# APM32F103xD register map
File version: 1.0
CPU: CM3 r2p1, little endian, no MPU, no FPU, 4 interrupt priority bits
Registers are 32-bit, read-write, reset 0x0 unless marked. A register's access mark holds for its fields unless they carry their own. Offsets are from the block's base; [hi:lo] are bit positions.

## IWDT — Independent watchdog
Base 0x40003000
0x00 KEY wo — Key register (IWDT_KEY)
  [15:0] KEY — Key value
0x04 PSC — Frequency Divider register (IWDT_PSC)
  [2:0] PSC — Prescaler divider
0x08 CNTRLD reset 0xFFF — Reload values register (IWDT_CNTRLD)
  [11:0] CNTRLD — Watchdog counter reload value
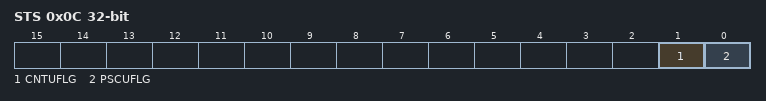
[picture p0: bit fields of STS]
0x0C STS ro — Status register (IWDT_STS)
  [1] CNTUFLG — Watchdog counter reload value update
  [0] PSCUFLG — Watchdog prescaler value update

## WWDT — Window watchdog
Base 0x40002C00
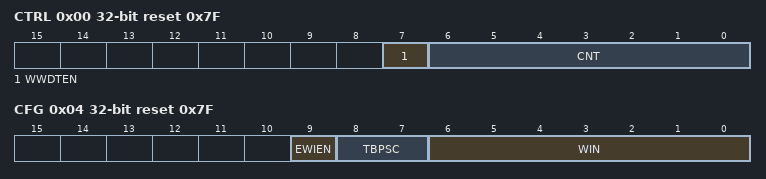
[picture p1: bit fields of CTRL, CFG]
0x00 CTRL reset 0x7F — Control register (WWDT_CTRL)
  [7] WWDTEN — Activation bit
  [6:0] CNT — 7-bit counter (MSB to LSB)
0x04 CFG reset 0x7F — Configuration register (WWDT_CFG)
  [9] EWIEN — Early Wakeup Interrupt
  [8:7] TBPSC — Timer Base
  [6:0] WIN — 7-bit window value
0x08 STS — Status register (WWDT_STS)
  [0] EWIFLG — Early Wakeup Interrupt

## RTC — Real time clock
Base 0x40002800
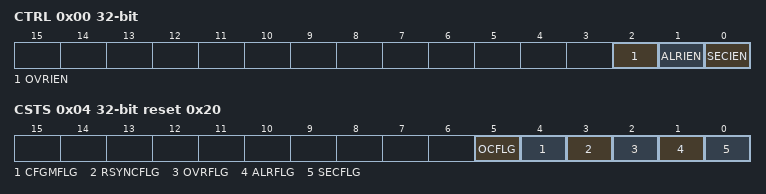
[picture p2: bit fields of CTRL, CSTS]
0x00 CTRL — Control register
  [2] OVRIEN — Overflow interrupt Enable
  [1] ALRIEN — Alarm interrupt Enable
  [0] SECIEN — Second interrupt Enable
0x04 CSTS access per field reset 0x20 — Control and State register
  [5] OCFLG ro — RTC operation OFF
  [4] CFGMFLG rw — Configuration Flag
  [3] RSYNCFLG rw — Registers Synchronized Flag
  [2] OVRFLG rw — Overflow Flag
  [1] ALRFLG rw — Alarm Flag
  [0] SECFLG rw — Second Flag
0x08 PSCRLDH wo — RTC predivision loading register High Bit
  [3:0] PSCRLDH — RTC Prescaler Load Register High
0x0C PSCRLDL wo reset 0x8000 — RTC predivision loading register Low Bit
  [15:0] PSCRLDL — RTC Prescaler Divider Register Low
0x10 PSCH ro — RTC predivider remainder register High Bit
  [3:0] PSCH — RTC prescaler divider register high
0x14 PSCL ro reset 0x8000 — RTC predivider remainder register Low Bit
  [15:0] PSCL — RTC prescaler divider register Low
0x18 CNTH — RTC count register High Bit
  [15:0] CNTH — RTC counter register high
0x1C CNTL — RTC count register Low Bit
  [15:0] CNTL — RTC counter register Low
0x20 ALRH wo reset 0xFFFF — RTC alarm clock register High Bit
  [15:0] ALRH — RTC alarm register high
0x24 ALRL wo reset 0xFFFF — RTC alarm clock register Low Bit
  [15:0] ALRL — RTC alarm register low

## SPI1 — Serial peripheral interface
Base 0x40013000
Same registers: SPI2 0x40003800, SPI3 0x40003C00
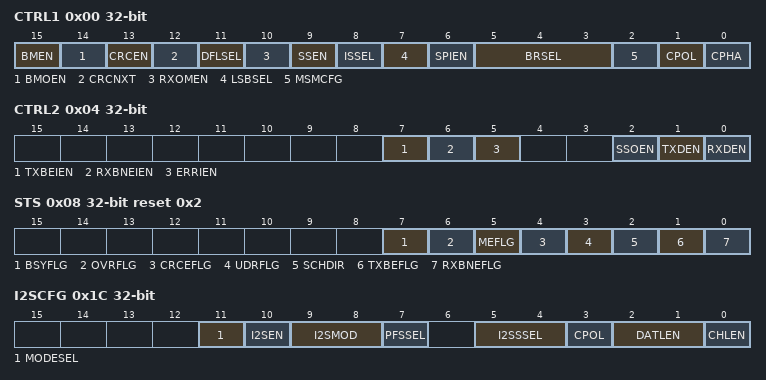
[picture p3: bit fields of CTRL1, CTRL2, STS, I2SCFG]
0x00 CTRL1 — control register 1
  [15] BMEN — Bidirectional data mode enable
  [14] BMOEN — Output enable in bidirectional mode
  [13] CRCEN — Hardware CRC calculation enable
  [12] CRCNXT — CRC transfer next
  [11] DFLSEL — Data frame format
  [10] RXOMEN — Receive only
  [9] SSEN — Software slave management
  [8] ISSEL — Internal slave select
  [7] LSBSEL — Frame format
  [6] SPIEN — SPI enable
  [5:3] BRSEL — Baud rate control
  [2] MSMCFG — Master selection
  [1] CPOL — Clock polarity
  [0] CPHA — Clock phase
0x04 CTRL2 — control register 2
  [7] TXBEIEN — Tx buffer empty interrupt enable
  [6] RXBNEIEN — RX buffer not empty interrupt enable
  [5] ERRIEN — Error interrupt enable
  [2] SSOEN — SS output enable
  [1] TXDEN — Tx buffer DMA enable
  [0] RXDEN — Rx buffer DMA enable
0x08 STS access per field reset 0x2 — status register
  [7] BSYFLG ro — Busy flag
  [6] OVRFLG ro — Overrun flag
  [5] MEFLG ro — Mode fault
  [4] CRCEFLG rw — CRC error flag
  [3] UDRFLG ro — Underrun flag
  [2] SCHDIR ro — Channel side
  [1] TXBEFLG ro — Transmit buffer empty
  [0] RXBNEFLG ro — Receive buffer not empty
0x0C DATA
  [15:0] DATA
0x10 CRCPOLY reset 0x7 — CRC polynomial register
  [15:0] CRCPOLY
0x14 RXCRC ro
  [15:0] RXCRC
0x18 TXCRC ro
  [15:0] TXCRC
0x1C I2SCFG — I2S configuration register
  [11] MODESEL — I2S mode selection
  [10] I2SEN — I2S Enable
  [9:8] I2SMOD — I2S configuration mode
  [7] PFSSEL — PCM frame synchronization
  [5:4] I2SSSEL — I2S standard selection
  [3] CPOL — Steady state clock polarity
  [2:1] DATLEN — Data length to be transferred
  [0] CHLEN — Channel length (number of bits per audio channel)
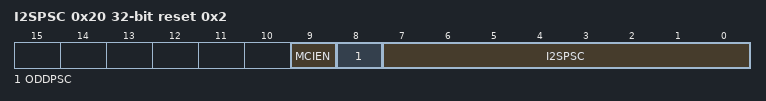
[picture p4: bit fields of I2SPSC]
0x20 I2SPSC reset 0x2 — I2S prescaler register
  [9] MCIEN — Master clock output enable
  [8] ODDPSC — Odd factor for the prescaler
  [7:0] I2SPSC — I2S Linear prescaler
